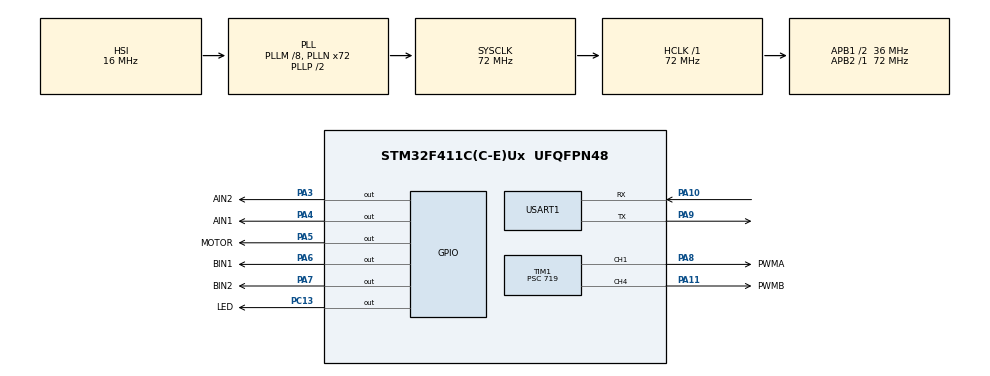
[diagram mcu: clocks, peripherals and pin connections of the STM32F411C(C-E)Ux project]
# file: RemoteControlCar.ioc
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Mcu.Family=STM32F4
Mcu.Name=STM32F411C(C-E)Ux
Mcu.Package=UFQFPN48
NVIC.PriorityGroup=NVIC_PRIORITYGROUP_4
NVIC.USART1_IRQn=true\:0\:0\:false\:false\:true\:true\:true\:true
PA10.Mode=Asynchronous
PA10.Signal=USART1_RX
PA11.GPIO_Label=PWMB
PA11.GPIO_PuPd=GPIO_PULLDOWN
PA11.Signal=S_TIM1_CH4
PA13.Mode=Serial_Wire
PA13.Signal=SYS_JTMS-SWDIO
PA14.Mode=Serial_Wire
PA14.Signal=SYS_JTCK-SWCLK
PA3.GPIO_Label=AIN2
PA3.GPIO_PuPd=GPIO_NOPULL
PA3.GPIO_Speed=GPIO_SPEED_FREQ_HIGH
PA3.Signal=GPIO_Output
PA4.GPIO_Label=AIN1
PA4.GPIO_PuPd=GPIO_NOPULL
PA4.GPIO_Speed=GPIO_SPEED_FREQ_HIGH
PA4.Signal=GPIO_Output
PA5.GPIO_Label=MOTOR
PA5.GPIO_PuPd=GPIO_NOPULL
PA5.GPIO_Speed=GPIO_SPEED_FREQ_HIGH
PA5.Signal=GPIO_Output
PA6.GPIO_Label=BIN1
PA6.GPIO_PuPd=GPIO_NOPULL
PA6.GPIO_Speed=GPIO_SPEED_FREQ_HIGH
PA6.Signal=GPIO_Output
PA7.GPIO_Label=BIN2
PA7.GPIO_PuPd=GPIO_NOPULL
PA7.GPIO_Speed=GPIO_SPEED_FREQ_HIGH
PA7.Signal=GPIO_Output
PA8.GPIO_Label=PWMA
PA8.GPIO_PuPd=GPIO_PULLDOWN
PA8.Signal=S_TIM1_CH1
PA9.Mode=Asynchronous
PA9.Signal=USART1_TX
PC13-ANTI_TAMP.GPIO_Label=LED
PC13-ANTI_TAMP.GPIO_PuPd=GPIO_NOPULL
PC13-ANTI_TAMP.Signal=GPIO_Output
ProjectManager.HeapSize=0x200
ProjectManager.StackSize=0x400
ProjectManager.TargetToolchain=Makefile
RCC.48MHZClocksFreq_Value=36000000
RCC.AHBFreq_Value=72000000
RCC.APB1CLKDivider=RCC_HCLK_DIV2
RCC.APB1Freq_Value=36000000
RCC.APB1TimFreq_Value=72000000
RCC.APB2Freq_Value=72000000
RCC.APB2TimFreq_Value=72000000
RCC.CortexFreq_Value=72000000
RCC.HCLKFreq_Value=72000000
RCC.HSE_VALUE=25000000
RCC.HSI_VALUE=16000000
RCC.LSE_VALUE=32768
RCC.PLLM=8
RCC.PLLN=72
RCC.SYSCLKFreq_VALUE=72000000
RCC.SYSCLKSource=RCC_SYSCLKSOURCE_PLLCLK
RCC.VCOOutputFreq_Value=144000000
SH.S_TIM1_CH1.0=TIM1_CH1,PWM Generation1 CH1
SH.S_TIM1_CH4.0=TIM1_CH4,PWM Generation4 CH4
TIM1.Channel-PWM\ Generation1\ CH1=TIM_CHANNEL_1
TIM1.Channel-PWM\ Generation4\ CH4=TIM_CHANNEL_4
TIM1.Period=1999
TIM1.Prescaler=719
USART1.VirtualMode=VM_ASYNC
VP_TIM1_VS_ClockSourceINT.Mode=Internal
board=custom

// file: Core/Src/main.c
/* USER CODE BEGIN Header */
/**
 ******************************************************************************
 * @file           : main.c
 * @brief          : Main program body
 ******************************************************************************
 * @attention
 *
 * Copyright (c) 2024 STMicroelectronics.
 * All rights reserved.
 *
 * This software is licensed under terms that can be found in the LICENSE file
 * in the root directory of this software component.
 * If no LICENSE file comes with this software, it is provided AS-IS.
 *
 ******************************************************************************
 */
/* USER CODE END Header */
#include "main.h"
#include "tim.h"
#include "usart.h"
#include "gpio.h"

/* USER CODE BEGIN Includes */
#include "control.h"
#include "bluetooth.h"
/* USER CODE END Includes */

void SystemClock_Config(void);

int main(void)
{

  /* MCU Configuration--------------------------------------------------------*/

  /* Reset of all peripherals, Initializes the Flash interface and the Systick. */
  HAL_Init();

  /* Configure the system clock */
  SystemClock_Config();

  /* Initialize all configured peripherals */
  MX_GPIO_Init();
  MX_USART1_UART_Init();
  MX_TIM1_Init();
  /* USER CODE BEGIN 2 */
  CONTROL_Init();
  BLUETOOTH_Init();
  /* USER CODE END 2 */

  /* Infinite loop */
  while (1)
  {

  }
}

void SystemClock_Config(void)
{
  RCC_OscInitTypeDef RCC_OscInitStruct = {0};
  RCC_ClkInitTypeDef RCC_ClkInitStruct = {0};

  /** Configure the main internal regulator output voltage
  */
  __HAL_RCC_PWR_CLK_ENABLE();
  __HAL_PWR_VOLTAGESCALING_CONFIG(PWR_REGULATOR_VOLTAGE_SCALE1);

  /** Initializes the RCC Oscillators according to the specified parameters
  * in the RCC_OscInitTypeDef structure.
  */
  RCC_OscInitStruct.OscillatorType = RCC_OSCILLATORTYPE_HSI;
  RCC_OscInitStruct.HSIState = RCC_HSI_ON;
  RCC_OscInitStruct.HSICalibrationValue = RCC_HSICALIBRATION_DEFAULT;
  RCC_OscInitStruct.PLL.PLLState = RCC_PLL_ON;
  RCC_OscInitStruct.PLL.PLLSource = RCC_PLLSOURCE_HSI;
  RCC_OscInitStruct.PLL.PLLM = 8;
  RCC_OscInitStruct.PLL.PLLN = 72;
  RCC_OscInitStruct.PLL.PLLP = RCC_PLLP_DIV2;
  RCC_OscInitStruct.PLL.PLLQ = 4;
  if (HAL_RCC_OscConfig(&RCC_OscInitStruct) != HAL_OK)
  {
    Error_Handler();
  }

  /** Initializes the CPU, AHB and APB buses clocks
  */
  RCC_ClkInitStruct.ClockType = RCC_CLOCKTYPE_HCLK|RCC_CLOCKTYPE_SYSCLK
                              |RCC_CLOCKTYPE_PCLK1|RCC_CLOCKTYPE_PCLK2;
  RCC_ClkInitStruct.SYSCLKSource = RCC_SYSCLKSOURCE_PLLCLK;
  RCC_ClkInitStruct.AHBCLKDivider = RCC_SYSCLK_DIV1;
  RCC_ClkInitStruct.APB1CLKDivider = RCC_HCLK_DIV2;
  RCC_ClkInitStruct.APB2CLKDivider = RCC_HCLK_DIV1;

  if (HAL_RCC_ClockConfig(&RCC_ClkInitStruct, FLASH_LATENCY_2) != HAL_OK)
  {
    Error_Handler();
  }
}

void Error_Handler(void)
{
  __disable_irq();
  while (1)
  {
  }
}
